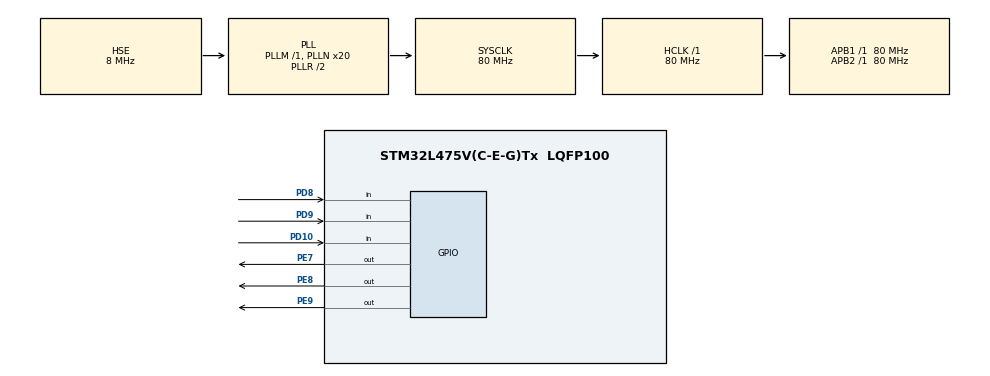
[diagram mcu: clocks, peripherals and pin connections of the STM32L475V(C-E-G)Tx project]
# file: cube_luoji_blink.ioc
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Mcu.Family=STM32L4
Mcu.Name=STM32L475V(C-E-G)Tx
Mcu.Package=LQFP100
NVIC.PriorityGroup=NVIC_PRIORITYGROUP_4
PD10.GPIO_PuPd=GPIO_PULLDOWN
PD10.Signal=GPIO_Input
PD8.GPIO_PuPd=GPIO_PULLDOWN
PD8.Signal=GPIO_Input
PD9.GPIO_PuPd=GPIO_PULLDOWN
PD9.Signal=GPIO_Input
PE7.GPIO_PuPd=GPIO_PULLUP
PE7.GPIO_Speed=GPIO_SPEED_FREQ_HIGH
PE7.PinState=GPIO_PIN_SET
PE7.Signal=GPIO_Output
PE8.GPIO_ModeDefaultOutputPP=GPIO_MODE_OUTPUT_PP
PE8.GPIO_PuPd=GPIO_PULLUP
PE8.GPIO_Speed=GPIO_SPEED_FREQ_HIGH
PE8.PinState=GPIO_PIN_SET
PE8.Signal=GPIO_Output
PE9.GPIO_PuPd=GPIO_PULLUP
PE9.GPIO_Speed=GPIO_SPEED_FREQ_HIGH
PE9.PinState=GPIO_PIN_SET
PE9.Signal=GPIO_Output
PH0-OSC_IN\ (PH0).Mode=HSE-External-Oscillator
PH0-OSC_IN\ (PH0).Signal=RCC_OSC_IN
PH1-OSC_OUT\ (PH1).Mode=HSE-External-Oscillator
PH1-OSC_OUT\ (PH1).Signal=RCC_OSC_OUT
ProjectManager.HeapSize=0x200
ProjectManager.StackSize=0x400
ProjectManager.TargetToolchain=MDK-ARM V5
RCC.ADCFreq_Value=32000000
RCC.AHBFreq_Value=80000000
RCC.APB1Freq_Value=80000000
RCC.APB1TimFreq_Value=80000000
RCC.APB2Freq_Value=80000000
RCC.APB2TimFreq_Value=80000000
RCC.CortexFreq_Value=80000000
RCC.HCLKFreq_Value=80000000
RCC.HSE_VALUE=8000000
RCC.HSI_VALUE=16000000
RCC.LSE_VALUE=32768
RCC.MSI_VALUE=4000000
RCC.PLLN=20
RCC.PLLSourceVirtual=RCC_PLLSOURCE_HSE
RCC.SYSCLKFreq_VALUE=80000000
RCC.SYSCLKSource=RCC_SYSCLKSOURCE_PLLCLK
RCC.USBFreq_Value=32000000
RCC.VCOOutputFreq_Value=160000000
board=custom

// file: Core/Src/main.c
/* USER CODE BEGIN Header */
/**
  ******************************************************************************
  * @file           : main.c
  * @brief          : Main program body
  ******************************************************************************
  * @attention
  *
  * <h2><center>&copy; Copyright (c) 2021 STMicroelectronics.
  * All rights reserved.</center></h2>
  *
  * This software component is licensed by ST under BSD 3-Clause license,
  * the "License"; You may not use this file except in compliance with the
  * License. You may obtain a copy of the License at:
  *                        opensource.org/licenses/BSD-3-Clause
  *
  ******************************************************************************
  */
/* USER CODE END Header */
#include "main.h"
#include "key.h"
#include "delay.h"
#include "usart.h"
#include "led.h"

UART_HandleTypeDef huart1;

void SystemClock_Config(void);
static void MX_GPIO_Init(void);

void led_switch(int i);
void test_key_led(void);
void test_usart(void);
void test_led_with_exti(void);

int main(void)
{

  /* MCU Configuration--------------------------------------------------------*/

  /* Reset of all peripherals, Initializes the Flash interface and the Systick. */
  HAL_Init();

  /* Configure the system clock */
  SystemClock_Config();
	 //_SysTick_Config(SystemCoreClock / RT_TICK_PER_SECOND);
	delay_init(80);

  /* Initialize all configured peripherals */
  MX_GPIO_Init();
  uart_init(115200);

  /* Infinite loop */
  /* USER CODE BEGIN WHILE */
  test_usart();
  /* USER CODE END 3 */
}

// key0 控制红绿蓝轮流亮
void test_key_led(){
	int i=0;
	HAL_GPIO_WritePin(GPIOE, GPIO_PIN_7,GPIO_PIN_RESET);
	while (1)
  {
    /* USER CODE END WHILE */
		 u8 k = KEY_Scan(0);
		switch(k){
			case KEY0_PRES:
				led_switch(i);
				i++;
				break;
			default:
				break;

		}
		delay_ms(10);

    /* USER CODE BEGIN 3 */
  }
}

// 用外部中断的方式实现，
void test_led_with_exti(){

	while(1){
		usart_send("\r\ntest_led_with_exti,%d\r\n");
		delay_ms(1000);
	}
}

//外部中断入口函数,
void HAL_GPIO_EXTI_Callback(uint16_t GPIO_Pin)
{
		usart_send("HAL_GPIO_EXTI_Callback\r\n");
    delay_ms(50);      //消抖
    switch(GPIO_Pin)
	{

		case  GPIO_PIN_8:		//控制LED_B灯状态翻转
			if( KEY2 == 0)
				LED_B_TogglePin;
			break;

		case  GPIO_PIN_9:		//控制LED_G灯状态翻转
			if( KEY1 == 0)
			LED_G_TogglePin;
			break;

		case  GPIO_PIN_10:		//控制LED_R灯状态翻转
			if( KEY0 == 0)
				LED_R_TogglePin;
			break;
		default:
			break;
	}
}

 // 串口的测试程序
void test_usart(){
	u8 len;
	u16 times = 0;
     while(1)
    {
        if(USART_RX_STA & 0x8000)  //最高位为1表示接收完成
        {
            len = USART_RX_STA & 0x3fff; //得到此次接收到的数据长度，0~13位表示接收到的长度
            usart_send("\r\n您发送的消息为:\r\n");
            HAL_UART_Transmit(&UART1_Handler, (uint8_t*)USART_RX_BUF, len, 1000);	//发送接收到的数据

            while(__HAL_UART_GET_FLAG(&UART1_Handler, UART_FLAG_TC) != SET);		//等待发送结束

            usart_send("\r\n\r\n");//插入换行
            USART_RX_STA = 0;
        }
        else
        {
            times++;

            if(times % 5000 == 0)
            {
                usart_send("\r\nALIENTEK 潘多拉 STM32L475 IOT开发板 串口实验\r\n");
                usart_send("正点原子@ALIENTEK\r\n\r\n\r\n");
            }

            if(times % 200 == 0)usart_send("请输入数据,以回车键结束\r\n");
            if(times % 30 == 0)LED_G_TogglePin; //闪烁LED,提示系统正在运行.

            delay_ms(10);
        }
    }
}

void led_switch(int i){
	HAL_GPIO_WritePin(GPIOE, GPIO_PIN_7 | GPIO_PIN_8 | GPIO_PIN_9, GPIO_PIN_SET);
	switch(i%3){
		case 0:
			HAL_GPIO_WritePin(GPIOE, GPIO_PIN_7 ,GPIO_PIN_RESET);
			break;
		case 1:
			HAL_GPIO_WritePin(GPIOE, GPIO_PIN_8 ,GPIO_PIN_RESET);
			break;
		case 2:
			HAL_GPIO_WritePin(GPIOE, GPIO_PIN_9  ,GPIO_PIN_RESET);
			break;
		default:
				break;
	}
}

void SystemClock_Config(void)
{
  RCC_OscInitTypeDef RCC_OscInitStruct = {0};
  RCC_ClkInitTypeDef RCC_ClkInitStruct = {0};
  RCC_PeriphCLKInitTypeDef PeriphClkInit = {0};

  /** Initializes the RCC Oscillators according to the specified parameters
  * in the RCC_OscInitTypeDef structure.
  */
  RCC_OscInitStruct.OscillatorType = RCC_OSCILLATORTYPE_HSE;
  RCC_OscInitStruct.HSEState = RCC_HSE_ON;
  RCC_OscInitStruct.PLL.PLLState = RCC_PLL_ON;
  RCC_OscInitStruct.PLL.PLLSource = RCC_PLLSOURCE_HSE;
  RCC_OscInitStruct.PLL.PLLM = 1;
  RCC_OscInitStruct.PLL.PLLN = 20;
  RCC_OscInitStruct.PLL.PLLP = RCC_PLLP_DIV7;
  RCC_OscInitStruct.PLL.PLLQ = RCC_PLLQ_DIV2;
  RCC_OscInitStruct.PLL.PLLR = RCC_PLLR_DIV2;
  if (HAL_RCC_OscConfig(&RCC_OscInitStruct) != HAL_OK)
  {
    Error_Handler();
  }
  /** Initializes the CPU, AHB and APB buses clocks
  */
  RCC_ClkInitStruct.ClockType = RCC_CLOCKTYPE_HCLK|RCC_CLOCKTYPE_SYSCLK
                              |RCC_CLOCKTYPE_PCLK1|RCC_CLOCKTYPE_PCLK2;
  RCC_ClkInitStruct.SYSCLKSource = RCC_SYSCLKSOURCE_PLLCLK;
  RCC_ClkInitStruct.AHBCLKDivider = RCC_SYSCLK_DIV1;
  RCC_ClkInitStruct.APB1CLKDivider = RCC_HCLK_DIV1;
  RCC_ClkInitStruct.APB2CLKDivider = RCC_HCLK_DIV1;

  if (HAL_RCC_ClockConfig(&RCC_ClkInitStruct, FLASH_LATENCY_4) != HAL_OK)
  {
    Error_Handler();
  }
  PeriphClkInit.PeriphClockSelection = RCC_PERIPHCLK_USART1;
  PeriphClkInit.Usart1ClockSelection = RCC_USART1CLKSOURCE_PCLK2;
  if (HAL_RCCEx_PeriphCLKConfig(&PeriphClkInit) != HAL_OK)
  {
    Error_Handler();
  }
  /** Configure the main internal regulator output voltage
  */
  if (HAL_PWREx_ControlVoltageScaling(PWR_REGULATOR_VOLTAGE_SCALE1) != HAL_OK)
  {
    Error_Handler();
  }
}

static void MX_GPIO_Init(void)
{
  GPIO_InitTypeDef GPIO_InitStruct = {0};

  /* GPIO Ports Clock Enable */
  __HAL_RCC_GPIOH_CLK_ENABLE();
  __HAL_RCC_GPIOE_CLK_ENABLE();
  __HAL_RCC_GPIOD_CLK_ENABLE();
  __HAL_RCC_GPIOA_CLK_ENABLE();

  /*Configure GPIO pin Output Level */
  HAL_GPIO_WritePin(GPIOE, GPIO_PIN_7|GPIO_PIN_8|GPIO_PIN_9, GPIO_PIN_SET);

  /*Configure GPIO pins : PE7 PE8 PE9 */
  GPIO_InitStruct.Pin = GPIO_PIN_7|GPIO_PIN_8|GPIO_PIN_9;
  GPIO_InitStruct.Mode = GPIO_MODE_OUTPUT_PP;
  GPIO_InitStruct.Pull = GPIO_PULLUP;
  GPIO_InitStruct.Speed = GPIO_SPEED_FREQ_HIGH;
  HAL_GPIO_Init(GPIOE, &GPIO_InitStruct);

  /*Configure GPIO pins : PD8 PD9 PD10 */
  GPIO_InitStruct.Pin = GPIO_PIN_8|GPIO_PIN_9|GPIO_PIN_10;
  GPIO_InitStruct.Mode = GPIO_MODE_IT_FALLING;
  GPIO_InitStruct.Pull = GPIO_PULLUP;
  HAL_GPIO_Init(GPIOD, &GPIO_InitStruct);

  /* EXTI interrupt init*/
  HAL_NVIC_SetPriority(EXTI9_5_IRQn, 0, 0);
  HAL_NVIC_EnableIRQ(EXTI9_5_IRQn);

  HAL_NVIC_SetPriority(EXTI15_10_IRQn, 0, 0);
  HAL_NVIC_EnableIRQ(EXTI15_10_IRQn);

}

void Error_Handler(void)
{
  __disable_irq();
  while (1)
   {
  }
}

/************************ (C) COPYRIGHT STMicroelectronics *****END OF FILE****/
